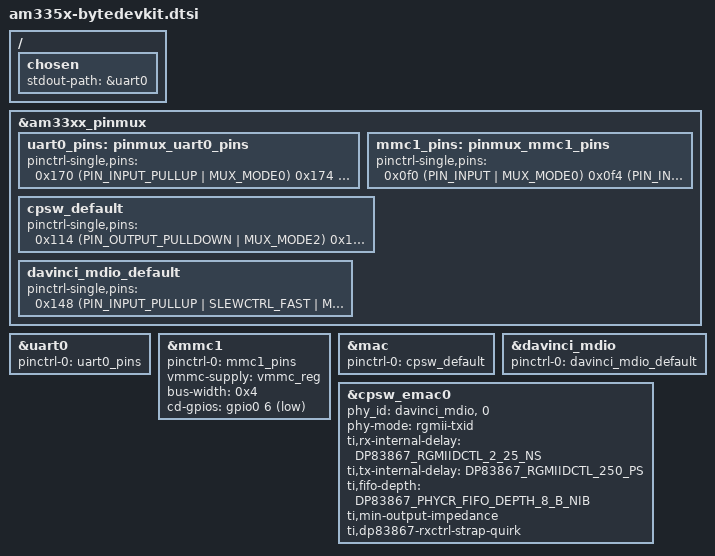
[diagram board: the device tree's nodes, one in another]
// SPDX-License-Identifier: GPL-2.0
/*
 * Copyright (C) 2018 bytes at work AG
 *
 * Based on am335x-evm.dts
 *
 * Copyright (C) 2012 Texas Instruments Incorporated - http://www.ti.com/
 */

/ {
	chosen {
		stdout-path = &uart0;
	};
};

&am33xx_pinmux {
	uart0_pins: pinmux_uart0_pins {
		pinctrl-single,pins = <
			0x170 (PIN_INPUT_PULLUP | MUX_MODE0)	/* uart0_rxd.uart0_rxd */
			0x174 (PIN_OUTPUT_PULLDOWN | MUX_MODE0)	/* uart0_txd.uart0_txd */
		>;
	};

	mmc1_pins: pinmux_mmc1_pins {
		pinctrl-single,pins = <
			0x0f0 (PIN_INPUT | MUX_MODE0)		/* mmc0_dat0.mmc0_dat0 */
			0x0f4 (PIN_INPUT | MUX_MODE0)		/* mmc0_dat1.mmc0_dat1 */
			0x0f8 (PIN_INPUT | MUX_MODE0)		/* mmc0_dat2.mmc0_dat2 */
			0x0fc (PIN_INPUT | MUX_MODE0)		/* mmc0_dat3.mmc0_dat3 */
			0x100 (PIN_INPUT | MUX_MODE0)		/* mmc0_clk.mmc0_clk */
			0x104 (PIN_INPUT | MUX_MODE0)		/* mmc0_cmd.mmc0_cmd */
			0x160 (PIN_INPUT_PULLUP | MUX_MODE7)	/* spi0_cs1.gpio0_6 */
		>;
	};

	cpsw_default: cpsw_default {
		pinctrl-single,pins = <
			/* Slave 1 */
			0x114 (PIN_OUTPUT_PULLDOWN | MUX_MODE2)	/* mii1_txen.rgmii1_tctl */
			0x118 (PIN_INPUT_PULLDOWN | MUX_MODE2)	/* mii1_rxdv.rgmii1_rctl */
			0x11c (PIN_OUTPUT_PULLDOWN | MUX_MODE2)	/* mii1_txd3.rgmii1_td3 */
			0x120 (PIN_OUTPUT_PULLDOWN | MUX_MODE2)	/* mii1_txd2.rgmii1_td2 */
			0x124 (PIN_OUTPUT_PULLDOWN | MUX_MODE2)	/* mii1_txd1.rgmii1_td1 */
			0x128 (PIN_OUTPUT_PULLDOWN | MUX_MODE2)	/* mii1_txd0.rgmii1_td0 */
			0x12c (PIN_OUTPUT_PULLDOWN | MUX_MODE2)	/* mii1_txclk.rgmii1_tclk */
			0x130 (PIN_INPUT_PULLDOWN | MUX_MODE2)	/* mii1_rxclk.rgmii1_rclk */
			0x134 (PIN_INPUT_PULLDOWN | MUX_MODE2)	/* mii1_rxd3.rgmii1_rd3 */
			0x138 (PIN_INPUT_PULLDOWN | MUX_MODE2)	/* mii1_rxd2.rgmii1_rd2 */
			0x13c (PIN_INPUT_PULLDOWN | MUX_MODE2)	/* mii1_rxd1.rgmii1_rd1 */
			0x140 (PIN_INPUT_PULLDOWN | MUX_MODE2)	/* mii1_rxd0.rgmii1_rd0 */
		>;
	};

	davinci_mdio_default: davinci_mdio_default {
		pinctrl-single,pins = <
			/* MDIO */
			0x148 (PIN_INPUT_PULLUP | SLEWCTRL_FAST | MUX_MODE0)	/* mdio_data.mdio_data */
			0x14c (PIN_OUTPUT_PULLUP | MUX_MODE0)			/* mdio_clk.mdio_clk */
		>;
	};
};

&uart0 {
	pinctrl-names = "default";
	pinctrl-0 = <&uart0_pins>;
	status = "okay";

	u-boot,dm-spl;
};

&mmc1 {
	pinctrl-names = "default";
	pinctrl-0 = <&mmc1_pins>;
	status = "okay";

	vmmc-supply = <&vmmc_reg>;
	bus-width = <0x4>;
	cd-gpios = <&gpio0 6 GPIO_ACTIVE_LOW>;
};

&mac {
	pinctrl-names = "default";
	pinctrl-0 = <&cpsw_default>;
	status = "okay";
};

&davinci_mdio {
	pinctrl-names = "default";
	pinctrl-0 = <&davinci_mdio_default>;
	status = "okay";
};

&cpsw_emac0 {
	phy_id = <&davinci_mdio>, <0>;
	phy-mode = "rgmii-txid";
	ti,rx-internal-delay = <DP83867_RGMIIDCTL_2_25_NS>;
	ti,tx-internal-delay = <DP83867_RGMIIDCTL_250_PS>;
	ti,fifo-depth = <DP83867_PHYCR_FIFO_DEPTH_8_B_NIB>;
	ti,min-output-impedance;
	ti,dp83867-rxctrl-strap-quirk;
};
